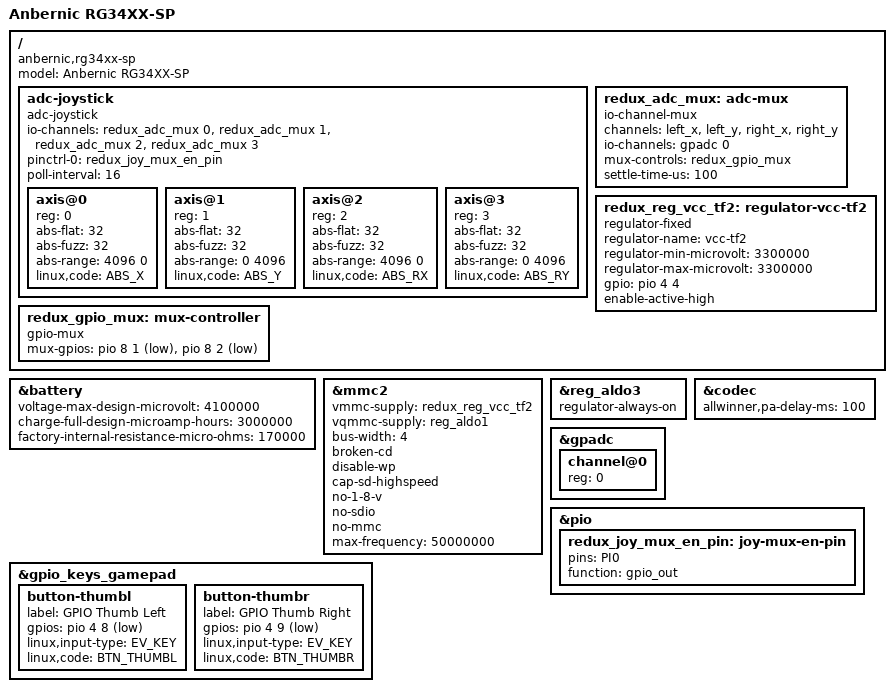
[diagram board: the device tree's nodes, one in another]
// SPDX-License-Identifier: (GPL-2.0-only OR BSD-2-Clause)
/*
 * Anbernic RG34XX-SP, Redux draft device tree (Phase 2).
 *
 * DRAFT, NOT BOOTED. Written 2026-11-13 by the Redux Kernel Research chat from:
 *  - upstream sun50i-h700-anbernic-rg35xx-sp.dts (torvalds/linux 97d73c8, v7.4-rc2), included below;
 *  - the stick wiring in stock reference/stock-202505/board.dts (ANBERNIC-keys node);
 * Original text, not copied from any other project's patches.
 *
 * What this adds on top of the upstream RG35XX SP tree:
 *  1. Analog sticks via upstream adc-joystick + io-channel-mux (no out-of-tree driver).
 *  2. The CPU OPP table of decision Q2: upstream's H616 table with ROCKNIX's H700 changes, 1512 MHz
 *     as boost (off by default) (sun50i-h700-redux-cpu-opp.dtsi).
 *  3. GPU OPPs 420-600 MHz on the fixed 0.94 V shared rail (sun50i-h700-redux-gpu-opp.dtsi).
 *  4. Battery charge voltage capped at stock's 4.10 V (upstream's RG35XX tree says 4.20 V).
 *  5. Speaker amplifier delay 100 ms, as stock (needs the Redux sun4i-codec patch; without it the
 *     property is ignored and mainline's 700 ms applies).
 *  6. Stick-click buttons L3/R3 on PE8/PE9 (stock keyL3/keyR3; same pins as upstream RG35XX-H).
 * What it deliberately does NOT add:
 *  - Display/panel nodes. Mainline has none for the H616 yet; the panel must come from the
 *    display patch set AND a panel identified at boot (u-boot DT selection). Never guess a panel.
 *
 * Thermal: decision Q1 (Dale, 2026-11-14) keeps stock's thermal settings, so
 * sun50i-h700-redux-stock-thermal.dtsi is included: CPU critical trip 115 C, no GPU/VE/DDR trips.
 */

#include "sun50i-h700-anbernic-rg35xx-sp.dts"
#include "sun50i-h700-redux-gpu-opp.dtsi"
#include "sun50i-h700-redux-cpu-opp.dtsi"
#include "sun50i-h700-redux-stock-thermal.dtsi"

/ {
	model = "Anbernic RG34XX-SP";
	compatible = "anbernic,rg34xx-sp", "allwinner,sun50i-h700";

	/*
	 * Sticks. Stock: GPADC channel 0 behind a 4-way analog mux; mux select A0/A1 = PI1/PI2,
	 * mux enable PI0 (stock amux-en-gpios <bank 8, pin 0>, driven high). Same wiring as the
	 * upstream RG35XX-H tree. Axis order and signs below are UNVERIFIED: confirm with evtest
	 * (ROCKNIX inverts the right stick on this model, relative to its own driver).
	 * Stock polls at 20 ms; upstream RG35XX-H uses 60 ms. 16 ms is one 60 Hz frame.
	 */
	adc-joystick {
		compatible = "adc-joystick";
		io-channels = <&redux_adc_mux 0>, <&redux_adc_mux 1>,
			      <&redux_adc_mux 2>, <&redux_adc_mux 3>;
		pinctrl-0 = <&redux_joy_mux_en_pin>;
		pinctrl-names = "default";
		poll-interval = <16>;
		#address-cells = <1>;
		#size-cells = <0>;

		axis@0 {
			reg = <0>;
			abs-flat = <32>;
			abs-fuzz = <32>;
			abs-range = <4096 0>;	/* left X, sign to verify */
			linux,code = <ABS_X>;
		};

		axis@1 {
			reg = <1>;
			abs-flat = <32>;
			abs-fuzz = <32>;
			abs-range = <0 4096>;	/* left Y, sign to verify */
			linux,code = <ABS_Y>;
		};

		axis@2 {
			reg = <2>;
			abs-flat = <32>;
			abs-fuzz = <32>;
			abs-range = <4096 0>;	/* right X, reversed vs RG35XX-H, to verify */
			linux,code = <ABS_RX>;
		};

		axis@3 {
			reg = <3>;
			abs-flat = <32>;
			abs-fuzz = <32>;
			abs-range = <0 4096>;	/* right Y, reversed vs RG35XX-H, to verify */
			linux,code = <ABS_RY>;
		};
	};

	redux_adc_mux: adc-mux {
		compatible = "io-channel-mux";
		channels = "left_x", "left_y", "right_x", "right_y";
		#io-channel-cells = <1>;
		io-channels = <&gpadc 0>;
		io-channel-names = "parent";
		mux-controls = <&redux_gpio_mux>;
		settle-time-us = <100>;
	};

	/*
	 * Second card slot (TF2) power: stock sdc2 "pwr-gpios" = PE4, driven high (W3.3 finding 1).
	 * UNVERIFIED on mainline; same pin and level as stock.
	 */
	redux_reg_vcc_tf2: regulator-vcc-tf2 {
		compatible = "regulator-fixed";
		regulator-name = "vcc-tf2";
		regulator-min-microvolt = <3300000>;
		regulator-max-microvolt = <3300000>;
		gpio = <&pio 4 4 GPIO_ACTIVE_HIGH>;	/* PE4 */
		enable-active-high;
	};

	redux_gpio_mux: mux-controller {
		compatible = "gpio-mux";
		mux-gpios = <&pio 8 1 GPIO_ACTIVE_LOW>,	/* PI1 = stock A0 */
			    <&pio 8 2 GPIO_ACTIVE_LOW>;	/* PI2 = stock A1 */
		#mux-control-cells = <0>;
	};
};

/*
 * Battery, from stock's AXP2202 settings (board.dts bat-power-supply): charge target 4100 mV
 * (pmu_init_chgvol), capacity 3000 mAh (pmu_battery_cap), resistance 170 mOhm (pmu_battery_rdc).
 * Charge current stays at upstream's 1024 mA (stock: 1500 mA): decision Q5 (Dale, 2026-11-14),
 * until the charging temperature check K14 on the device.
 */
&battery {
	voltage-max-design-microvolt = <4100000>;
	charge-full-design-microamp-hours = <3000000>;
	factory-internal-resistance-micro-ohms = <170000>;
};

/*
 * Second card slot (TF2), as stock wires it (W3.3 finding 1, R30): 4-bit SD on the PC pins, card
 * detect polled (stock sets broken-cd beside its PE22 line), slot power PE4, I/O supply ALDO1.
 * ALDO1 has no voltage constraints upstream, so the MMC core can only switch it on and off, as
 * stock does (sunxi-dis-signal-vol-sw): its voltage is never changed. 50 MHz, no 1.8 V modes.
 * UNVERIFIED: not run on hardware.
 */
&mmc2 {
	vmmc-supply = <&redux_reg_vcc_tf2>;
	vqmmc-supply = <&reg_aldo1>;
	bus-width = <4>;
	broken-cd;
	disable-wp;
	cap-sd-highspeed;
	no-1-8-v;
	no-sdio;
	no-mmc;
	max-frequency = <50000000>;
	status = "okay";
};

/*
 * ALDO3 is always-on in stock with no named consumer (W3.3 finding 3, R30). Upstream leaves it
 * unused, so mainline would switch it off at late init. Keep it on, at the voltage the boot
 * chain left, until a device check shows what it feeds.
 */
&reg_aldo3 {
	regulator-always-on;
};

&codec {
	allwinner,pa-delay-ms = <100>;	/* stock pa-pin-msleep-0 */
};

&gpadc {
	#address-cells = <1>;
	#size-cells = <0>;
	status = "okay";

	channel@0 {
		reg = <0>;
	};
};

&gpio_keys_gamepad {
	button-thumbl {
		label = "GPIO Thumb Left";
		gpios = <&pio 4 8 GPIO_ACTIVE_LOW>; /* PE8 */
		linux,input-type = <EV_KEY>;
		linux,code = <BTN_THUMBL>;
	};

	button-thumbr {
		label = "GPIO Thumb Right";
		gpios = <&pio 4 9 GPIO_ACTIVE_LOW>; /* PE9 */
		linux,input-type = <EV_KEY>;
		linux,code = <BTN_THUMBR>;
	};
};

&pio {
	/* PI0: stock amux-en, output high while the sticks are read. */
	redux_joy_mux_en_pin: joy-mux-en-pin {
		pins = "PI0";
		function = "gpio_out";
	};
};
